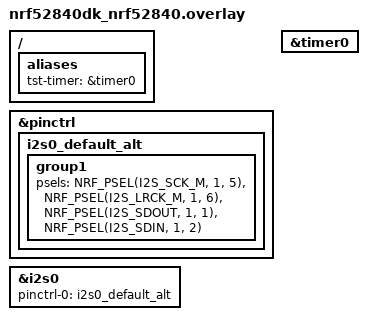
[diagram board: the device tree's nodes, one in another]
/* i2s-node0 is the transmitter/receiver */

/ {
	aliases {
		tst-timer = &timer0;
	};
};

&pinctrl {
	i2s0_default_alt: i2s0_default_alt {
		group1 {
			psels = <NRF_PSEL(I2S_SCK_M, 1, 5)>,
				<NRF_PSEL(I2S_LRCK_M, 1, 6)>,
				<NRF_PSEL(I2S_SDOUT, 1, 1)>,
				<NRF_PSEL(I2S_SDIN, 1, 2)>;
		};
	};
};

i2s_dut: &i2s0 {
	status = "okay";
	pinctrl-0 = <&i2s0_default_alt>;
	pinctrl-names = "default";
};

&timer0 {
	status = "okay";
};
